# ESP32-S2 register map
Vendor: ESPRESSIF SYSTEMS (SHANGHAI) CO., LTD.; Series: ESP32 S-Series; File version: 20
CPU: Xtensa LX7 r0p0, little endian, no MPU, no FPU, 0 interrupt priority bits
Address unit: 32 bits
Registers are 32-bit, read-write, reset 0x0 unless marked. A register's access mark holds for its fields unless they carry their own. Offsets are from the block's base; [hi:lo] are bit positions; {n}, {i} and the like mark numbered series.

## GPIO — General Purpose Input/Output
Base 0x3F404000
0x00 BT_SELECT — GPIO bit select register
  [31:0] BT_SEL — Reserved
0x04 OUT — GPIO0 ~ 31 output register
  [31:0] DATA_ORIG — GPIO0 ~ 31 output value in simple GPIO output mode. The values of bit0 ~ bit31 correspond to the output value of GPIO0 ~ GPIO31 respectively. Bit22 ~ bit25 are invalid.
0x08 OUT_W1TS wo — GPIO0 ~ 31 output bit set register
  [31:0] OUT_W1TS — GPIO0 ~ 31 output set register. If the value 1 is written to a bit here, the corre- sponding bit in GPIO_OUT_REG will be set to 1. Recommended operation: use this register to set GPIO_OUT_REG.
0x0C OUT_W1TC wo — GPIO0 ~ 31 output bit clear register
  [31:0] OUT_W1TC — GPIO0 ~ 31 output clear register. If the value 1 is written to a bit here, the cor- responding bit in GPIO_OUT_REG will be cleared. Recommended operation: use this register to clear GPIO_OUT_REG.
0x10 OUT1 — GPIO32 ~ 53 output register
  [21:0] DATA_ORIG — GPIO32 ~ 53 output value in simple GPIO output mode. The values of bit0 ~ bit13 correspond to GPIO32 ~ GPIO45. Bit14 ~ bit21 are invalid.
0x14 OUT1_W1TS wo — GPIO32 ~ 53 output bit set register
  [21:0] OUT1_W1TS — GPIO32 ~ 53 output value set register. If the value 1 is written to a bit here, the corresponding bit in GPIO_OUT1_REG will be set to 1. Recommended operation: use this register to set GPIO_OUT1_REG.
0x18 OUT1_W1TC wo — GPIO32 ~ 53 output bit clear register
  [21:0] OUT1_W1TC — GPIO32 ~ 53 output value clear register. If the value 1 is written to a bit here, the corresponding bit in GPIO_OUT1_REG will be cleared. Recommended operation: use this register to clear GPIO_OUT1_REG.
0x1C SDIO_SELECT — GPIO SDIO selection register
  [7:0] SDIO_SEL — Reserved
0x20 ENABLE — GPIO0 ~ 31 output enable register
  [31:0] DATA — GPIO0~31 output enable register.
0x24 ENABLE_W1TS wo — GPIO0 ~ 31 output enable bit set register
  [31:0] ENABLE_W1TS — GPIO0 ~ 31 output enable set register. If the value 1 is written to a bit here, the corresponding bit in GPIO_ENABLE_REG will be set to 1. Recommended operation: use this register to set GPIO_ENABLE_REG.
0x28 ENABLE_W1TC wo — GPIO0 ~ 31 output enable bit clear register
  [31:0] ENABLE_W1TC — GPIO0 ~ 31 output enable clear register. If the value 1 is written to a bit here, the corresponding bit in GPIO_ENABLE_REG will be cleared. Recommended operation: use this register to clear GPIO_ENABLE_REG.
0x2C ENABLE1 — GPIO32 ~ 53 output enable register
  [21:0] DATA — GPIO32~53 output enable register.
0x30 ENABLE1_W1TS wo — GPIO32 ~ 53 output enable bit set register
  [21:0] ENABLE1_W1TS — GPIO32 ~ 53 output enable set register. If the value 1 is written to a bit here, the corresponding bit in GPIO_ENABLE1_REG will be set to 1. Recommended operation: use this register to set GPIO_ENABLE1_REG.
0x34 ENABLE1_W1TC wo — GPIO32 ~ 53 output enable bit clear register
  [21:0] ENABLE1_W1TC — GPIO32 ~ 53 output enable clear register. If the value 1 is written to a bit here, the corresponding bit in GPIO_ENABLE1_REG will be cleared. Recommended operation: use this register to clear GPIO_ENABLE1_REG.
0x38 STRAP ro — Bootstrap pin value register
  [15:0] STRAPPING — GPIO strapping values: bit4 ~ bit2 correspond to stripping pins GPIO45, GPIO0, and GPIO46 respectively.
0x3C IN ro — GPIO0 ~ 31 input register
  [31:0] DATA_NEXT — GPIO0 ~ 31 input value. Each bit represents a pad input value, 1 for high level and 0 for low level.
0x40 IN1 ro — GPIO32 ~ 53 input register
  [21:0] IN_DATA1_NEXT — GPIO32 ~ 53 input value. Each bit represents a pad input value.
0x44 STATUS — GPIO0 ~ 31 interrupt status register
  [31:0] INTERRUPT — GPIO0 ~ 31 interrupt status register.
0x48 STATUS_W1TS wo — GPIO0 ~ 31 interrupt status bit set register
  [31:0] STATUS_W1TS — GPIO0 ~ 31 interrupt status set register. If the value 1 is written to a bit here, the corresponding bit in GPIO_STATUS_INTERRUPT will be set to 1. Recommended operation: use this register to set GPIO_STATUS_INTERRUPT.
0x4C STATUS_W1TC wo — GPIO0 ~ 31 interrupt status bit clear register
  [31:0] STATUS_W1TC — GPIO0 ~ 31 interrupt status clear register. If the value 1 is written to a bit here, the corresponding bit in GPIO_STATUS_INTERRUPT will be cleared. Recommended operation: use this register to clear GPIO_STATUS_INTERRUPT.
0x50 STATUS1 — GPIO32 ~ 53 interrupt status register
  [21:0] INTERRUPT — GPIO32 ~ 53 interrupt status register.
0x54 STATUS1_W1TS wo — GPIO32 ~ 53 interrupt status bit set register
  [21:0] STATUS1_W1TS — GPIO32 ~ 53 interrupt status set register. If the value 1 is written to a bit here, the corresponding bit in GPIO_STATUS1_REG will be set to 1. Recommended operation: use this register to set GPIO_STATUS1_REG.
0x58 STATUS1_W1TC wo — GPIO32 ~ 53 interrupt status bit clear register
  [21:0] STATUS1_W1TC — GPIO32 ~ 53 interrupt status clear register. If the value 1 is written to a bit here, the corresponding bit in GPIO_STATUS1_REG will be cleared. Recommended operation: use this register to clear GPIO_STATUS1_REG.
0x5C PCPU_INT ro — GPIO0 ~ 31 PRO_CPU interrupt status register
  [31:0] PROCPU_INT — GPIO0 ~ 31 PRO_CPU interrupt status. This interrupt status is corresponding to the bit in GPIO_STATUS_REG when assert (high) enable signal (bit13 of GPIO_PINn_REG).
0x60 PCPU_NMI_INT ro — GPIO0 ~ 31 PRO_CPU non-maskable interrupt status register
  [31:0] PROCPU_NMI_INT — GPIO0 ~ 31 PRO_CPU non-maskable interrupt status. This interrupt sta- tus is corresponding to the bit in GPIO_STATUS_REG when assert (high) enable signal (bit 14 of GPIO_PINn_REG).
0x64 CPUSDIO_INT ro — GPIO0 ~ 31 CPU SDIO interrupt status register
  [31:0] SDIO_INT — GPIO0~31 CPU SDIO interrupt status.
0x68 PCPU_INT1 ro — GPIO32 ~ 53 PRO_CPU interrupt status register
  [21:0] PROCPU1_INT — GPIO32 ~ 53 PRO_CPU interrupt status. This interrupt status is corresponding to the bit in GPIO_STATUS1_REG when assert (high) enable signal (bit 13 of GPIO_PINn_REG).
0x6C PCPU_NMI_INT1 ro — GPIO32 ~ 53 PRO_CPU non-maskable interrupt status register
  [21:0] PROCPU_NMI1_INT — GPIO32 ~ 53 PRO_CPU non-maskable interrupt status. This interrupt status is corresponding to bit in GPIO_STATUS1_REG when assert (high) enable signal (bit 14 of GPIO_PINn_REG).
0x70 CPUSDIO_INT1 ro — GPIO32 ~ 53 CPU SDIO interrupt status register
  [21:0] SDIO1_INT — GPIO32~53 CPU SDIO interrupt status.
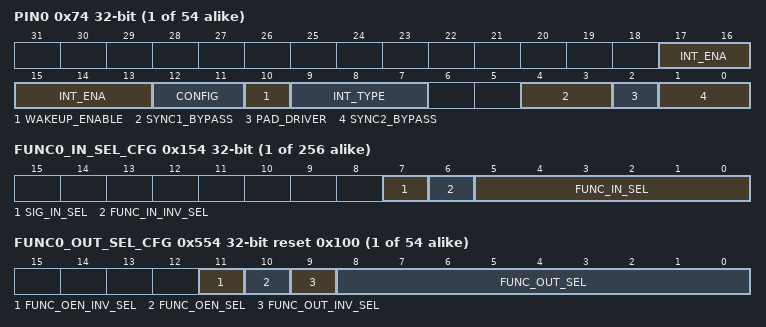
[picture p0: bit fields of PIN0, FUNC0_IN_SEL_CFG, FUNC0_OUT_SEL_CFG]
{0x74+4i} PIN{i} (i=0..53) — Configuration for GPIO pin {i}
  [17:13] INT_ENA — Interrupt enable bits. bit13: CPU interrupt enabled; bit14: CPU non-maskable interrupt enabled.
  [12:11] CONFIG — Reserved
  [10] WAKEUP_ENABLE — GPIO wake-up enable bit, only wakes up the CPU from Light-sleep.
  [9:7] INT_TYPE — Interrupt type selection. 0: GPIO interrupt disabled; 1: rising edge trigger; 2: falling edge trigger; 3: any edge trigger; 4: low level trigger; 5: high level trigger. (R/W)
  [4:3] SYNC1_BYPASS — For the first stage synchronization, GPIO input data can be synchro- nized on either edge of the APB clock. 0: no synchronization; 1: synchronized on falling edge; 2 and 3: synchronized on rising edge.
  [2] PAD_DRIVER — Pad driver selection. 0: normal output; 1: open drain output..
  [1:0] SYNC2_BYPASS — For the second stage synchronization, GPIO input data can be syn- chronized on either edge of the APB clock. 0: no synchronization; 1: synchronized on falling edge; 2 and 3: synchronized on rising edge.
0x14C STATUS_NEXT ro — GPIO0 ~ 31 interrupt source register
  [31:0] STATUS_INTERRUPT_NEXT — Interrupt source signal of GPIO0 ~ 31, could be rising edge interrupt, falling edge interrupt, level sensitive interrupt and any edge interrupt.
0x150 STATUS_NEXT1 ro — GPIO32 ~ 53 interrupt source register
  [21:0] STATUS1_INTERRUPT_NEXT — Interrupt source signal of GPIO32 ~ 53.
{0x154+4i} FUNC{i}_IN_SEL_CFG (i=0..255) — Peripheral function {i} input selection register
  [7] SIG_IN_SEL — Bypass GPIO matrix. 1: route signals via GPIO matrix, 0: connect signals directly to peripheral configured in IO_MUX.
  [6] FUNC_IN_INV_SEL — Invert the input value. 1: invert enabled; 0: invert disabled.
  [5:0] FUNC_IN_SEL — Selection control for peripheral input signal m, selects a pad from the 54 GPIO matrix pads to connect this input signal. Or selects 0x38 for a constantly high input or 0x3C for a constantly low input.
{0x554+4i} FUNC{i}_OUT_SEL_CFG (i=0..53) reset 0x100 — Peripheral output selection for GPIO {i}
  [11] FUNC_OEN_INV_SEL — 0: Do not invert the output enable signal; 1: Invert the output enable signal.
  [10] FUNC_OEN_SEL — 0: Use output enable signal from peripheral; 1: Force the output enable signal to be sourced from bit n of GPIO_ENABLE_REG.
  [9] FUNC_OUT_INV_SEL — 0: Do not invert the output value; 1: Invert the output value.
  [8:0] FUNC_OUT_SEL — Selection control for GPIO output n. If a value s (0<=s<256) is written to this field, the peripheral output signal s will be connected to GPIO output n. If a value 256 is written to this field, bit n of GPIO_OUT_REG/GPIO_OUT1_REG and GPIO_ENABLE_REG/GPIO_ENABLE1_REG will be selected as the output value and output enable.
0x62C CLOCK_GATE reset 0x1 — GPIO clock gating register
  [0] CLK_EN — Clock gating enable bit. If set to 1, the clock is free running.
0x6FC REG_DATE reset 0x1905061 — Version control register
  [27:0] DATE
